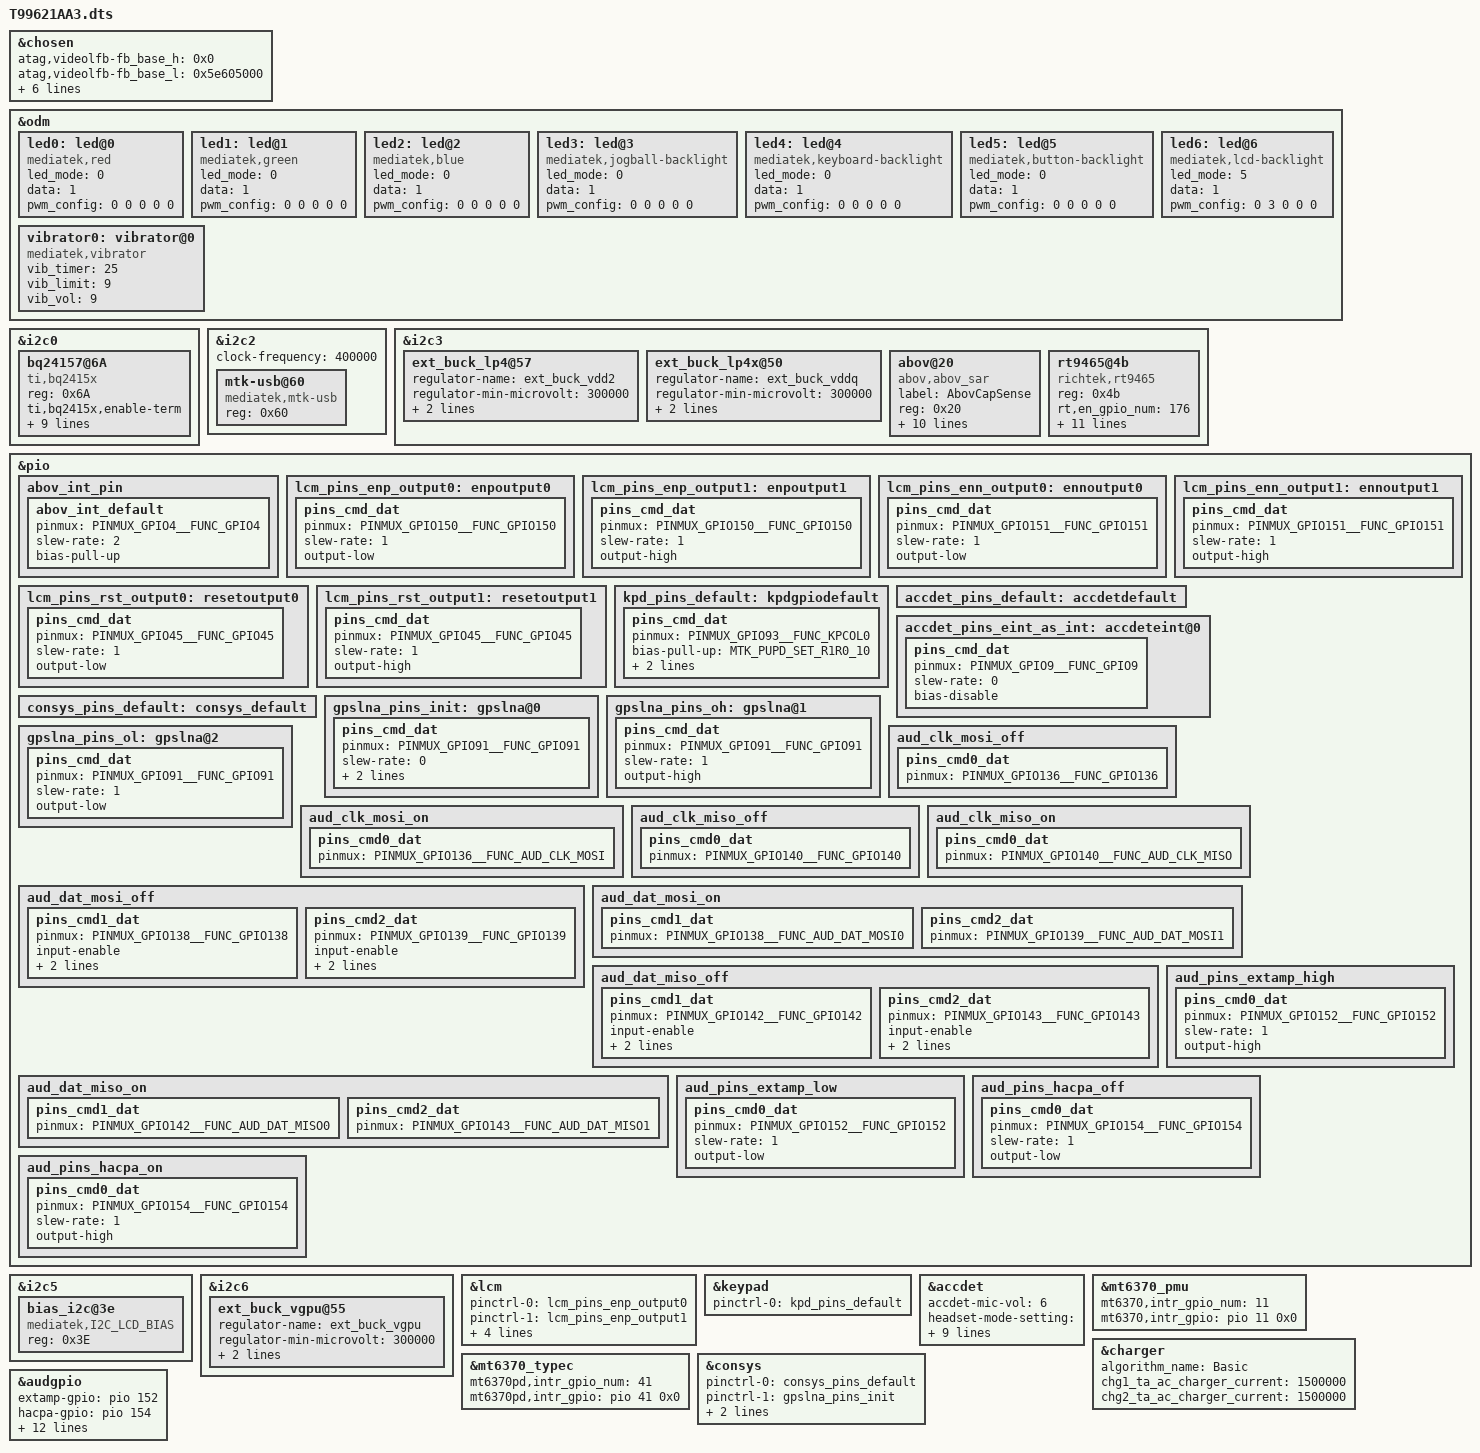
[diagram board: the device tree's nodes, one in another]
// SPDX-License-Identifier: GPL-2.0+
/*
 * Copyright (c) 2019 MediaTek Inc.
 *
 */

#include <dt-bindings/interrupt-controller/arm-gic.h>
#include <dt-bindings/interrupt-controller/irq.h>
#include <dt-bindings/pinctrl/mt6761-pinfunc.h>
#include <dt-bindings/mmc/mt6761-msdc.h>
#include <dt-bindings/clock/mt6761-clk.h>

/dts-v1/;
/plugin/;

/* chosen */
&chosen {

	/* fpga may has no lk, we need to specify display info here */
	/* fb buffer is reserved using this dts by memory node above */
	atag,videolfb-fb_base_h = <0x0>;
	atag,videolfb-fb_base_l = <0x5e605000>;
	atag,videolfb-islcmfound = <1>;
	/* because no lk, so lcm is not inited */
	atag,videolfb-islcm_inited = <0>;
	atag,videolfb-fps= <6000>;
	atag,videolfb-vramSize= <0x017bb000>;
	atag,videolfb-lcmname= "nt35521_hd_dsi_vdo_truly_rt5081_drv";
};

&odm {
	led0:led@0 {
		compatible = "mediatek,red";
		led_mode = <0>;
		data = <1>;
		pwm_config = <0 0 0 0 0>;
	};
	led1:led@1 {
		compatible = "mediatek,green";
		led_mode = <0>;
		data = <1>;
		pwm_config = <0 0 0 0 0>;
	};
	led2:led@2 {
		compatible = "mediatek,blue";
		led_mode = <0>;
		data = <1>;
		pwm_config = <0 0 0 0 0>;
	};
	led3:led@3 {
		compatible = "mediatek,jogball-backlight";
		led_mode = <0>;
		data = <1>;
		pwm_config = <0 0 0 0 0>;
	};
	led4:led@4 {
		compatible = "mediatek,keyboard-backlight";
		led_mode = <0>;
		data = <1>;
		pwm_config = <0 0 0 0 0>;
	};
	led5:led@5 {
		compatible = "mediatek,button-backlight";
		led_mode = <0>;
		data = <1>;
		pwm_config = <0 0 0 0 0>;
	};
	led6:led@6 {
		compatible = "mediatek,lcd-backlight";
		led_mode = <5>;
		data = <1>;
		pwm_config = <0 3 0 0 0>;
	};
	vibrator0:vibrator@0 {
		compatible = "mediatek,vibrator";
		vib_timer = <25>;
		vib_limit = <9>;
		vib_vol= <9>;
	};
};

// + Bug585485, jinpeng1@WT,20200917, add, add charger(bq24157) driver
&i2c0 {
	bq24157@6A {
		compatible = "ti,bq2415x";
		reg = <0x6A>;

		/*ti,charging-disabled;*/
		ti,bq2415x,enable-term;

		ti,bq2415x,current-sensor-mohm = <55>;
		ti,bq2415x,charge-voltage = <4420>;
		ti,bq2415x,charge-current = <1550>;
		ti,bq2415x,input-current-limit = <1500>;
		ti,bq2415x,input-voltage-limit = <4400>;/*vindpm threshold*/
		ti,bq2415x,vbatlow-volt = <3500>;
		ti,bq2415x,term-current = <150>;
		ti,bq2415x,safety-max-charge-current = <1550>;
		ti,bq2415x,safety-max-charge-voltage = <4420>;
	};
};
// - Bug585485, jinpeng1@WT,20200917,add, add charger(bq24157) driver

&i2c2 {
	#address-cells = <1>;
	#size-cells = <0>;
	clock-frequency = <400000>;

	mtk-usb@60 {
		compatible = "mediatek,mtk-usb";
		reg = <0x60>;
		status = "okay";
	};
};

&i2c3 {
	ext_buck_lp4@57 {
		regulator-name ="ext_buck_vdd2";
		regulator-min-microvolt = <300000>;
		regulator-max-microvolt = <1300000>;
		vsel_pin = <0>;
	};

	ext_buck_lp4x@50 {
		regulator-name ="ext_buck_vddq";
		regulator-min-microvolt = <300000>;
		regulator-max-microvolt = <1300000>;
		vsel_pin = <1>;
	};
// +bug584769,wangyongfei.wt,20200923,add,sarsensor
	abov@20 {
		label = "AbovCapSense";
		compatible = "abov,abov_sar";
		reg = <0x20>;
		interrupt-parent = <&pio>;
		interrupts = <4 IRQ_TYPE_EDGE_FALLING 4 0>;
	     	abov,irq-gpio = <&pio 4 0>;
		pinctrl-names = "abov_int_default";
		pinctrl-0 = <&abov_int_default>;
		cap,use_channel = <0x0f>;
		cap,use_channel_top = <0x01>;
		cap,use_channel_bottom = <0x00>;
		cap,scan_period = <0x02>;
		reg_array_len = <2>;
		reg_array_val = <0x18 0x5a 0x19 0x93>;
	};
// -bug584769,wangyongfei.wt,20200923,add,sarsensor
};

// +bug584769,wangyongfei.wt,20200923,add,sarsensor
&pio{
	abov_int_pin {
		abov_int_default: abov_int_default {
		/* active state */
		pinmux = <PINMUX_GPIO4__FUNC_GPIO4>;
		slew-rate = <2>;
		bias-pull-up;
	    };
	};
};
// -bug584769,wangyongfei.wt,20200923,add,sarsensor

&i2c5 {
	bias_i2c@3e {
		compatible = "mediatek,I2C_LCD_BIAS";
		reg = <0x3E>;
		status = "okay";
	};
};

&i2c6 {
	ext_buck_vgpu@55 {
		regulator-name ="ext_buck_vgpu";
		regulator-min-microvolt = <300000>;
		regulator-max-microvolt = <1300000>;
		vsel_pin = <2>;
	};
};

/*LCM start*/
&lcm {
	pinctrl-names = "state_enp_output0","state_enp_output1", "state_enn_output0",
		"state_enn_output1","state_reset_output0", "state_reset_output1";
	pinctrl-0 = <&lcm_pins_enp_output0>;
	pinctrl-1 = <&lcm_pins_enp_output1>;
	pinctrl-2 = <&lcm_pins_enn_output0>;
	pinctrl-3 = <&lcm_pins_enn_output1>;
	pinctrl-4 = <&lcm_pins_rst_output0>;
	pinctrl-5 = <&lcm_pins_rst_output1>;
	status = "okay";
};
&pio {
	lcm_pins_enp_output0: enpoutput0 {
		pins_cmd_dat {
			pinmux = <PINMUX_GPIO150__FUNC_GPIO150>;
			slew-rate = <1>;
			output-low;
		};
	};
	lcm_pins_enp_output1: enpoutput1 {
		pins_cmd_dat {
			pinmux = <PINMUX_GPIO150__FUNC_GPIO150>;
			slew-rate = <1>;
			output-high;
		};
	};
	lcm_pins_enn_output0: ennoutput0 {
		pins_cmd_dat {
			pinmux = <PINMUX_GPIO151__FUNC_GPIO151>;
			slew-rate = <1>;
			output-low;
		};
	};
	lcm_pins_enn_output1: ennoutput1 {
		pins_cmd_dat {
			pinmux = <PINMUX_GPIO151__FUNC_GPIO151>;
			slew-rate = <1>;
			output-high;
		};
	};
	lcm_pins_rst_output0: resetoutput0 {
		pins_cmd_dat {
			pinmux = <PINMUX_GPIO45__FUNC_GPIO45>;
			slew-rate = <1>;
			output-low;
		};
	};
	lcm_pins_rst_output1: resetoutput1 {
		pins_cmd_dat {
			pinmux = <PINMUX_GPIO45__FUNC_GPIO45>;
			slew-rate = <1>;
			output-high;
		};
	};
};
/*LCM end*/

&keypad {
	pinctrl-names = "default";
	pinctrl-0 = <&kpd_pins_default>;
};

&pio {
	kpd_pins_default: kpdgpiodefault {
		pins_cmd_dat {
			pinmux = <PINMUX_GPIO93__FUNC_KPCOL0>;
			bias-pull-up = <MTK_PUPD_SET_R1R0_10>;
			output-low;
			input-schmitt-enable;
		};
	};
};

&accdet {
	accdet-mic-vol = <6>;
	headset-mode-setting = <0x500 0x500 1 0x1f0 0x800 0x800 0x20 0x44>;
	accdet-plugout-debounce = <1>;
	accdet-mic-mode = <1>;
	headset-eint-level-pol = <8>;
	headset-three-key-threshold = <0 80 220 400>;//IRM1837 xiangyujie.wt 20201016 modify compatible with more headset
	headset-three-key-threshold-CDD = <0 121 192 600>;
	headset-four-key-threshold = <0 58 121 192 400>;
	pinctrl-names = "default", "state_eint_as_int";
	pinctrl-0 = <&accdet_pins_default>;
	pinctrl-1 = <&accdet_pins_eint_as_int>;
	status = "okay";
};
&pio {
	accdet_pins_default: accdetdefault {
	};
	accdet_pins_eint_as_int: accdeteint@0 {
		pins_cmd_dat {
			pinmux = <PINMUX_GPIO9__FUNC_GPIO9>;
			slew-rate = <0>;
			bias-disable;
		};
	};
};

&mt6370_pmu {
	mt6370,intr_gpio_num = <11>; /* direct defined GPIO num */
	mt6370,intr_gpio = <&pio 11 0x0>;
};

//+Bug326207, yangpingao@WT, add charger(bq24157) driver, 20190705
&charger {
	algorithm_name = "Basic";
	chg1_ta_ac_charger_current = <1500000>;
	chg2_ta_ac_charger_current = <1500000>;
};
//-Bug326207, yangpingao@WT, add charger(bq24157) driver, 20190705

&i2c3 {
	rt9465@4b {
		compatible = "richtek,rt9465";
		reg = <0x4b>;
		status = "okay";
		rt,en_gpio_num = <176>;
		rt,en_gpio = <&pio 176 0x0>;
		rt,intr_gpio_num = <23>; /* direct defined GPIO num */
		rt,intr_gpio = <&pio 23 0x0>;
		interrupt-names = "wdtmri";
		charger_name = "secondary_chg";
		ichg = <1500000>; /* uA */
		mivr = <4500000>; /* uV */
		cv = <4550000>; /* uV */
		ieoc = <700000>; /* uA */
		safety_timer = <12>; /* hour */
		en_st; /* safety timer */
		/* en_te; */
		en_wdt;
	};
};

&mt6370_typec {
	mt6370pd,intr_gpio_num = <41>; /* direct defined GPIO num */
	mt6370pd,intr_gpio = <&pio 41 0x0>;
};
/* CONSYS GPIO standardization */
&pio {
	consys_pins_default: consys_default {
	};
	gpslna_pins_init: gpslna@0 {
		pins_cmd_dat {
			pinmux = <PINMUX_GPIO91__FUNC_GPIO91>;
			slew-rate = <0>;
			bias-disable;
			output-low;
		};
	};
	gpslna_pins_oh: gpslna@1 {
		pins_cmd_dat {
			pinmux = <PINMUX_GPIO91__FUNC_GPIO91>;
			slew-rate = <1>;
			output-high;
		};
	};
	gpslna_pins_ol: gpslna@2 {
		pins_cmd_dat {
			pinmux = <PINMUX_GPIO91__FUNC_GPIO91>;
			slew-rate = <1>;
			output-low;
		};
	};
};
&consys {
	pinctrl-names = "default", "gps_lna_state_init",
		"gps_lna_state_oh", "gps_lna_state_ol";
	pinctrl-0 = <&consys_pins_default>;
	pinctrl-1 = <&gpslna_pins_init>;
	pinctrl-2 = <&gpslna_pins_oh>;
	pinctrl-3 = <&gpslna_pins_ol>;
	status = "okay";
};
/* CONSYS end */

/* AUDIO GPIO standardization */
&audgpio {
	extamp-gpio = <&pio 152 0x0>;
        /*ExtRIRM-7062 liujun5.wt add 20191016 for add voice hac feature*/
        hacpa-gpio = <&pio 154 0x0>;
	pinctrl-names = "aud_clk_mosi_off",
			"aud_clk_mosi_on",
			"aud_clk_miso_off",
			"aud_clk_miso_on",
			"aud_dat_mosi_off",
			"aud_dat_mosi_on",
			"aud_dat_miso_off",
			"aud_dat_miso_on",
			"extamp-pullhigh",
			"extamp-pulllow",
                        "aud_pins_hacpa_off",
                        "aud_pins_hacpa_on";
	pinctrl-0 = <&aud_clk_mosi_off>;
	pinctrl-1 = <&aud_clk_mosi_on>;
	pinctrl-2 = <&aud_clk_miso_off>;
	pinctrl-3 = <&aud_clk_miso_on>;
	pinctrl-4 = <&aud_dat_mosi_off>;
	pinctrl-5 = <&aud_dat_mosi_on>;
	pinctrl-6 = <&aud_dat_miso_off>;
	pinctrl-7 = <&aud_dat_miso_on>;
	pinctrl-8 = <&aud_pins_extamp_high>;
	pinctrl-9 = <&aud_pins_extamp_low>;
        pinctrl-10 = <&aud_pins_hacpa_off>;
        pinctrl-11 = <&aud_pins_hacpa_on>;
	status = "okay";
};/*ExtRIRM-7062 liujun5.wt add 20191016 for add voice hac feature*/

&pio {
	aud_clk_mosi_off: aud_clk_mosi_off {
		pins_cmd0_dat {
			pinmux = <PINMUX_GPIO136__FUNC_GPIO136>;
		};
	};

	aud_clk_mosi_on: aud_clk_mosi_on {
		pins_cmd0_dat {
			pinmux = <PINMUX_GPIO136__FUNC_AUD_CLK_MOSI>;
		};
	};

	aud_clk_miso_off: aud_clk_miso_off {
		pins_cmd0_dat {
			pinmux = <PINMUX_GPIO140__FUNC_GPIO140>;
		};
	};

	aud_clk_miso_on: aud_clk_miso_on {
		pins_cmd0_dat {
			pinmux = <PINMUX_GPIO140__FUNC_AUD_CLK_MISO>;
		};
	};

	aud_dat_mosi_off: aud_dat_mosi_off {
		pins_cmd1_dat {
			pinmux = <PINMUX_GPIO138__FUNC_GPIO138>;
			input-enable;
			slew-rate = <0>;
			bias-disable;
		};
		pins_cmd2_dat {
			pinmux = <PINMUX_GPIO139__FUNC_GPIO139>;
			input-enable;
			slew-rate = <0>;
			bias-disable;
		};
	};

	aud_dat_mosi_on: aud_dat_mosi_on {
		pins_cmd1_dat {
			pinmux = <PINMUX_GPIO138__FUNC_AUD_DAT_MOSI0>;
		};
		pins_cmd2_dat {
			pinmux = <PINMUX_GPIO139__FUNC_AUD_DAT_MOSI1>;
		};
	};

	aud_dat_miso_off: aud_dat_miso_off {
		pins_cmd1_dat {
			pinmux = <PINMUX_GPIO142__FUNC_GPIO142>;
			input-enable;
			slew-rate = <0>;
			bias-disable;
		};
		pins_cmd2_dat {
			pinmux = <PINMUX_GPIO143__FUNC_GPIO143>;
			input-enable;
			slew-rate = <0>;
			bias-disable;
		};
	};

	aud_dat_miso_on: aud_dat_miso_on {
		pins_cmd1_dat {
			pinmux = <PINMUX_GPIO142__FUNC_AUD_DAT_MISO0>;
		};
		pins_cmd2_dat {
			pinmux = <PINMUX_GPIO143__FUNC_AUD_DAT_MISO1>;
		};
	};

	aud_pins_extamp_high: aud_pins_extamp_high {
		pins_cmd0_dat {
			pinmux = <PINMUX_GPIO152__FUNC_GPIO152>;
			slew-rate = <1>;
			output-high;
		};
	};

	aud_pins_extamp_low: aud_pins_extamp_low {
		pins_cmd0_dat {
			pinmux = <PINMUX_GPIO152__FUNC_GPIO152>;
			slew-rate = <1>;
			output-low;

		};
	};
        /*+ExtRIRM-7062 liujun5.wt add 20191016 for add voice hac feature*/
        aud_pins_hacpa_off: aud_pins_hacpa_off {
                pins_cmd0_dat {
                        pinmux = <PINMUX_GPIO154__FUNC_GPIO154>;
                        slew-rate = <1>;
                        output-low;
                };
        };

        aud_pins_hacpa_on: aud_pins_hacpa_on {
                pins_cmd0_dat {
                        pinmux = <PINMUX_GPIO154__FUNC_GPIO154>;
                        slew-rate = <1>;
                        output-high;
                };
        };
        /*-ExtRIRM-7062 liujun5.wt add 20191016 for add voice hac feature*/

};
/* AUDIO end */

#include <T99621AA3/cust.dtsi>
#include "cust_mt6761_camera.dtsi"
#include "cust_mt6761_touch_720x1520.dtsi"
/*End of this file, DO NOT ADD ANYTHING HERE*/
